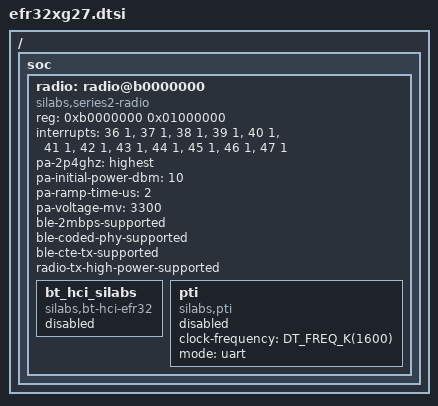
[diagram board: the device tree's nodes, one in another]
/*
 * Copyright (c) 2025 Silicon Laboratories Inc.
 *
 * SPDX-License-Identifier: Apache-2.0
 */

#include <silabs/xg27/xg27.dtsi>

/ {
	soc {
		radio: radio@b0000000 {
			compatible = "silabs,series2-radio";
			reg = <0xb0000000 0x01000000>;
			interrupt-names = "agc", "bufc", "frc_pri", "frc", "modem", "protimer",
					  "rac_rsm", "rac_seq", "rdmailbox", "rfsense", "synth",
					  "prortc";
			interrupts = <36 1>, <37 1>, <38 1>, <39 1>, <40 1>, <41 1>, <42 1>,
				     <43 1>, <44 1>, <45 1>, <46 1>, <47 1>;
			pa-2p4ghz = "highest";
			pa-initial-power-dbm = <10>;
			pa-ramp-time-us = <2>;
			pa-voltage-mv = <3300>;
			ble-2mbps-supported;
			ble-coded-phy-supported;
			ble-cte-tx-supported;
			radio-tx-high-power-supported;

			bt_hci_silabs: bt_hci_silabs {
				compatible = "silabs,bt-hci-efr32";
				status = "disabled";
			};

			pti: pti {
				compatible = "silabs,pti";
				clock-frequency = <DT_FREQ_K(1600)>;
				mode = "uart";
				status = "disabled";
			};
		};
	};
};
